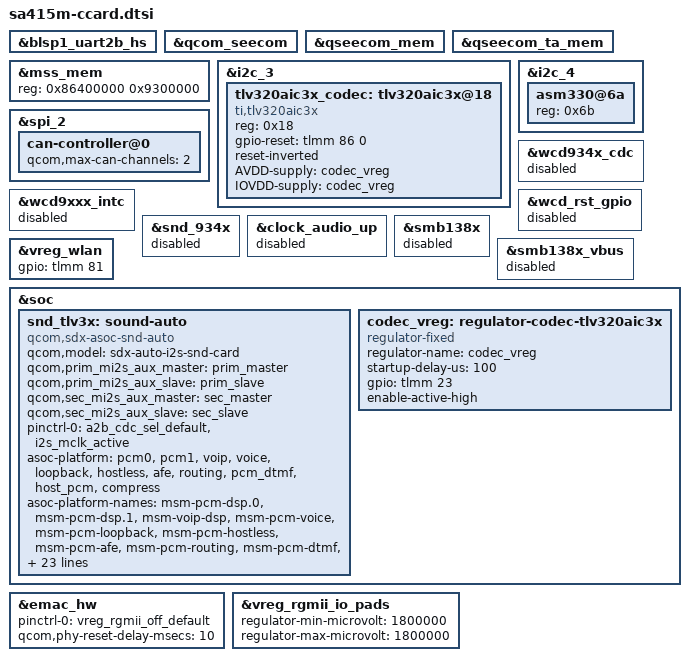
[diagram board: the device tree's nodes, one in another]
/* Copyright (c) 2019, The Linux Foundation. All rights reserved.
 *
 * This program is free software; you can redistribute it and/or modify
 * it under the terms of the GNU General Public License version 2 and
 * only version 2 as published by the Free Software Foundation.
 *
 * This program is distributed in the hope that it will be useful,
 * but WITHOUT ANY WARRANTY; without even the implied warranty of
 * MERCHANTABILITY or FITNESS FOR A PARTICULAR PURPOSE.  See the
 * GNU General Public License for more details.
 */

#include "sa415m-ttp.dtsi"
#include "sdxpoorwills-v2.dtsi"

&blsp1_uart2b_hs {
	status = "okay";
};

&qcom_seecom {
	status = "okay";
};

&qseecom_mem {
	status = "okay";
};

&qseecom_ta_mem {
	status = "okay";
};

&blsp1_uart2b_hs {
	status = "okay";
};

&mss_mem {
	reg = <0x86400000 0x9300000>;
};

&i2c_3 {
	tlv320aic3x_codec: tlv320aic3x@18 {
		compatible = "ti,tlv320aic3x";
		reg = <0x18>;
		gpio-reset = <&tlmm 86 0>;
		reset-inverted;
		AVDD-supply = <&codec_vreg>;
		IOVDD-supply = <&codec_vreg>;
	};
};

&i2c_4 {
	asm330@6a {
		reg = <0x6b>;
	};
};

&spi_2 {
	can-controller@0 {
		qcom,max-can-channels = <2>;
	};
};

&wcd934x_cdc {
	status = "disabled";
};

&wcd9xxx_intc {
	status = "disabled";
};

&wcd_rst_gpio {
	status = "disabled";
};

&snd_934x {
	status = "disabled";
};

&clock_audio_up {
	status = "disabled";
};

&smb138x {
	status = "disabled";
};

&smb138x_vbus {
	status = "disabled";
};

&vreg_wlan {
	gpio = <&tlmm 81 GPIO_ACTIVE_HIGH>;
};

&soc {
	snd_tlv3x: sound-auto {
		compatible = "qcom,sdx-asoc-snd-auto";
		qcom,model = "sdx-auto-i2s-snd-card";
		qcom,prim_mi2s_aux_master = <&prim_master>;
		qcom,prim_mi2s_aux_slave = <&prim_slave>;
		qcom,sec_mi2s_aux_master = <&sec_master>;
		qcom,sec_mi2s_aux_slave = <&sec_slave>;

		pinctrl-names = "default";
		pinctrl-0 = <&a2b_cdc_sel_default>, <&i2s_mclk_active>;

		asoc-platform = <&pcm0>, <&pcm1>, <&voip>, <&voice>,
				<&loopback>, <&hostless>, <&afe>, <&routing>,
				<&pcm_dtmf>, <&host_pcm>, <&compress>;
		asoc-platform-names = "msm-pcm-dsp.0", "msm-pcm-dsp.1",
				"msm-voip-dsp", "msm-pcm-voice",
				"msm-pcm-loopback", "msm-pcm-hostless",
				"msm-pcm-afe", "msm-pcm-routing",
				"msm-pcm-dtmf", "msm-voice-host-pcm",
				"msm-compress-dsp";
		asoc-cpu = <&dai_pri_auxpcm>, <&mi2s_prim>, <&mi2s_sec>,
				<&dtmf_tx>,
				<&rx_capture_tx>, <&rx_playback_rx>,
				<&tx_capture_tx>, <&tx_playback_rx>,
				<&afe_pcm_rx>, <&afe_pcm_tx>, <&afe_proxy_rx>,
				<&afe_proxy_tx>, <&incall_record_rx>,
				<&incall_record_tx>, <&incall_music_rx>,
				<&dai_pri_tdm_rx_0>, <&dai_pri_tdm_tx_0>,
				<&dai_sec_tdm_rx_0>, <&dai_sec_tdm_tx_0>,
				<&dai_sec_auxpcm>;
		asoc-cpu-names = "msm-dai-q6-auxpcm.1",
				"msm-dai-q6-mi2s.0", "msm-dai-q6-mi2s.1",
				"msm-dai-stub-dev.4", "msm-dai-stub-dev.5",
				"msm-dai-stub-dev.6", "msm-dai-stub-dev.7",
				"msm-dai-stub-dev.8", "msm-dai-q6-dev.224",
				"msm-dai-q6-dev.225", "msm-dai-q6-dev.241",
				"msm-dai-q6-dev.240", "msm-dai-q6-dev.32771",
				"msm-dai-q6-dev.32772", "msm-dai-q6-dev.32773",
				"msm-dai-q6-tdm.36864", "msm-dai-q6-tdm.36865",
				"msm-dai-q6-tdm.36880", "msm-dai-q6-tdm.36881",
				"msm-dai-q6-auxpcm.2";
		asoc-codec = <&tlv320aic3x_codec>, <&stub_codec>;
		asoc-codec-names = "tlv320aic3x-codec", "msm-stub-codec.1";
	};

	codec_vreg: regulator-codec-tlv320aic3x {
		compatible = "regulator-fixed";
		regulator-name = "codec_vreg";
		startup-delay-us = <100>;
		gpio = <&tlmm 23 GPIO_ACTIVE_HIGH>;
		enable-active-high;
	};
};

&emac_hw {
	/delete-property/ vreg_rgmii-supply;
	pinctrl-names = "default";
	pinctrl-0 = <&vreg_rgmii_off_default>;
	qcom,phy-reset-delay-msecs = <10>;
};

&vreg_rgmii_io_pads {
	regulator-min-microvolt = <1800000>;
	regulator-max-microvolt = <1800000>;
};
